# cslr_sgmii register map
Vendor: Texas Instruments
Peripheral module from a debugger description file.
Registers are 32-bit, access per field, reset 0x0 unless marked. A register's access mark holds for its fields unless they carry their own. Offsets are as the file gives them; lines under a group give offsets from that group; [hi:lo] are bit positions; {n}, {i} and the like mark numbered series; 'fields as' and 'values as' point back to an identical list; <NAME> marks a mode.

## SGMII — Serial Gigabit Media independent Interface
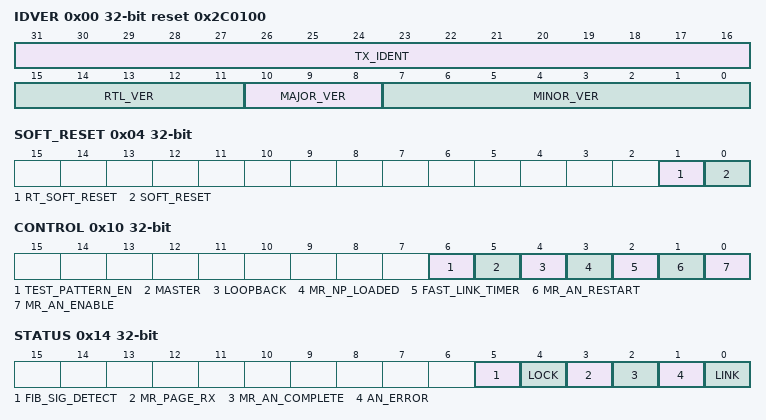
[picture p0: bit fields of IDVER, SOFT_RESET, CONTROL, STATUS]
0x00 IDVER ro reset 0x2C0100 — Identification and Version register
  [31:16] TX_IDENT — TX identification value
  [15:11] RTL_VER — RTL version value
  [10:8] MAJOR_VER — Major version value
  [7:0] MINOR_VER — Minor version value
0x04 SOFT_RESET access not given — Software Reset Register
  [1] RT_SOFT_RESET — Transmit and Receive Software Reset. Writing 1 to this bit causes the CPSGMII Transmit and Receive logic to be in reset condition
  [0] SOFT_RESET rw — Software reset - Writing a one to this bit causes the CPSGMII logic to be reset. Software reset occurs immediately
0x10 CONTROL
  [6] TEST_PATTERN_EN rw — Test Pattern Enable
  [5] MASTER rw — Master mode
  [4] LOOPBACK rw — Loop back mode. In loop back mode the transmit clock(TX_CLK) is used for transmit/receive and auto-negotiation is bypassed
  [3] MR_NP_LOADED rw — Next Page Loaded - Writing a one to this bit informs the auto-negotiation process that the next page register has been loaded. After writing a one to this bit, software should read the status register and clear this bit then the reset_np_loaded bit in the status register is asserted. This bit is not used when the SGMII_MODE input is asserted
  [2] FAST_LINK_TIMER rw — Fast link timer. 0 - The link timer value is 10ms in FIBER mode and 1.6ms in SGMII mode. 1 - The link timer value is 2us in FIBER and SGMII mode. This is included for test purposes.
  [1] MR_AN_RESTART rw — Auto-Negotiation restart
  [0] MR_AN_ENABLE rw — Auto-Negotiation enable
0x14 STATUS
  [5] FIB_SIG_DETECT ro — Fiber Signal Detect - This is the FIB_SIG_DETECT input pin
  [4] LOCK ro — Lock - This is the Lock input pin
  [3] MR_PAGE_RX ro — Next Page Received - This is set to 1 by the auto-negotiation state machine when the next page has been received. This bit is cleared to 0 by a host write of 1 to the mr_np_loaded bit in the CONTROL register. This value is not valid until the lock status bit is asserted
  [2] MR_AN_COMPLETE rw — Auto-negotiation complete. This value is not valid until the lock status bit is asserted
  [1] AN_ERROR rw — Auto-negotiation error. For SGMII mode an auto-negotiation error occurs when half duplex gigabit is commanded. For FIBER mode, auto-negotiation error occurs when both sides can not be full duplex This bit is not valid until the lock status bit is asserted
  [0] LINK rw — Link. This value is not valid until the lock status bit is asserted
0x18 MR_ADV_ABILITY — Advertised Ability Register
  [15:0] MR_ADV_ABILITY rw — Advertised Ability
0x1C MR_NP_TX — Next Page Transmit Register
  [15:0] MR_NP_TX rw — Next Page Transmit
0x20 MR_LP_ADV_ABILITY — Link Partner Advertised Ability Register
  [15:0] MR_LP_ADV_ABILITY rw — Link Partner Advertised Ability
0x24 MR_LP_NP_RX — Link Partner Next Page Received Register
  [15:0] MR_LP_NP_RX rw — Link Partner Next Page Received
0x30 TX_CFG rw — Transmit Configuration Register
  [31:0] TX_CFG — Transmit Configuration Register Output. This is a 32-bit general purpose output to be used to control the SERDES transmit configuration. These are the SERDES device specific configuration bits
0x34 RX_CFG rw — Receive Configuration Register
  [31:0] RX_CFG — Receive Configuration Register Output. This is a 32-bit general purpose output to be used to control the SERDES receive configuration. These are the SERDES device specific configuration bits
0x38 AUX_CFG rw — Auxiliary Configuration Register
  [31:0] AUX_CFG — Auxiliary Configuration Register Output. These are also specific to SERDES
0x40 DIAG_CLEAR — Diagnostics Clear Register
  [0] DIAG_CLEAR rw — Diagnostics Clear. Clears all diagnostic status bits when set to one. Some bits may be set back to one immediately following reset. The reset requires several clocks due to synchronizers
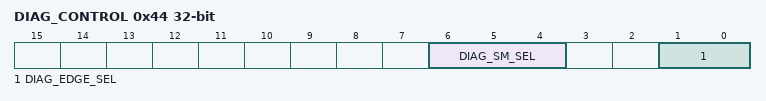
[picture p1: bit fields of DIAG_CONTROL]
0x44 DIAG_CONTROL — Diagnostics Control Register
  [6:4] DIAG_SM_SEL rw — Diagnostic Select - Determines which internal diagnostic bits are muxed onto diag_stat[15:0]
    1=HOLD_SIGNAL (Diagnostic Hold Signals); 2=SYNC_STATUS (Diagnostic Sync Status); 3=AN_STATUS (Diagnostic AN Status); 4=TXOS_STATUS (Diagnostic TXOS Status); 5=TXCG_STATUS (Diagnostic TXCG Status); 6=RXSM_LOW_STATUS (Diagnostic RXSM Status); 7=RXSM_HIGH_STATUS (Diagnostic RXSM Status)
  [1:0] DIAG_EDGE_SEL rw — Diagnostics Hold Signals Edge Select.
0x48 DIAG_STATUS ro — Diagnostics Status Register
  [15:0] DIAG_STATUS — Diagnostics Status
